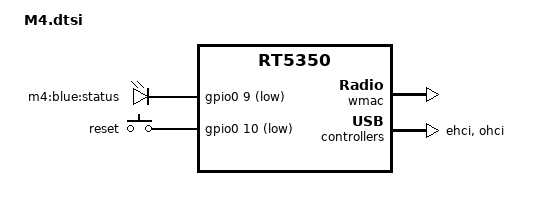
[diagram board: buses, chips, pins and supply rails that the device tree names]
#include "rt5350.dtsi"

#include <dt-bindings/gpio/gpio.h>
#include <dt-bindings/input/input.h>

/ {
	compatible = "poray,m4", "ralink,rt5350-soc";

	aliases {
		led-status = &led_status;
	};

	gpio-leds {
		compatible = "gpio-leds";

		led_status: status {
			label = "m4:blue:status";
			gpios = <&gpio0 9 GPIO_ACTIVE_LOW>;
		};
	};

	gpio-keys-polled {
		compatible = "gpio-keys-polled";
		poll-interval = <20>;

		reset {
			label = "reset";
			gpios = <&gpio0 10 GPIO_ACTIVE_LOW>;
			linux,code = <KEY_RESTART>;
		};
	};
};

&pinctrl {
	state_default: pinctrl0 {
		gpio {
			ralink,group = "i2c", "jtag", "uartf";
			ralink,function = "gpio";
		};
	};
};

&ethernet {
	mtd-mac-address = <&factory 0x4>;
};

&esw {
	mediatek,portmap = <0x2f>;
	mediatek,led_polarity = <1>;
};

&wmac {
	ralink,mtd-eeprom = <&factory 0>;
	ralink,led-polarity = <1>;
};

&ehci {
	status = "okay";
};

&ohci {
	status = "okay";
};
